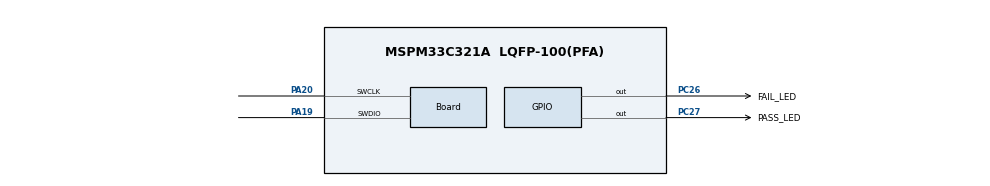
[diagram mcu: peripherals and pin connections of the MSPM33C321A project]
//@cliArgs --device "MSPM33C321A" --package "LQFP-100(PFA)" --part "Default"
//@v2CliArgs --device "MSPM33C321A" --package "LQFP-100(PFA)"
// @cliArgs --board /ti/boards/LP_MSPM33C321A --rtos nortos

/**
 * Import the modules used in this configuration.
 */
const GPIO   = scripting.addModule("/ti/driverlib/GPIO", {}, false);
const GPIO1  = GPIO.addInstance();
const HSADC  = scripting.addModule("/ti/driverlib/HSADC", {}, false);
const HSADC1 = HSADC.addInstance();
const SYSCTL = scripting.addModule("/ti/driverlib/SYSCTL");

/**
 * Write custom configuration values to the imported modules.
 */
GPIO1.$name                               = "GPIO_LEDS";
GPIO1.associatedPins.create(2);
GPIO1.associatedPins[0].$name             = "PASS_LED";
GPIO1.associatedPins[0].launchPadShortcut = "LED2GreenEn";
GPIO1.associatedPins[0].pin.$assign       = "PC27";
GPIO1.associatedPins[1].$name             = "FAIL_LED";
GPIO1.associatedPins[1].launchPadShortcut = "LED2RedEn";
GPIO1.associatedPins[1].pin.$assign       = "PC26";

const Board                       = scripting.addModule("/ti/driverlib/Board", {}, false);
Board.peripheral.$assign          = "DEBUGSS";
Board.peripheral.swclkPin.$assign = "PA20";
Board.peripheral.swdioPin.$assign = "PA19";

HSADC1.$name                 = "HSADC0";
HSADC1.enabledSOCs           = ["ADC_SOC_NUMBER0","ADC_SOC_NUMBER1","ADC_SOC_NUMBER10","ADC_SOC_NUMBER11","ADC_SOC_NUMBER12","ADC_SOC_NUMBER13","ADC_SOC_NUMBER14","ADC_SOC_NUMBER15","ADC_SOC_NUMBER2","ADC_SOC_NUMBER3","ADC_SOC_NUMBER4","ADC_SOC_NUMBER5","ADC_SOC_NUMBER6","ADC_SOC_NUMBER7","ADC_SOC_NUMBER8","ADC_SOC_NUMBER9"];
HSADC1.enabledSEQs           = ["ADC_SEQ_NUMBER1","ADC_SEQ_NUMBER2"];
HSADC1.seqEndSOC             = "ADC_SOC_NUMBER15";
HSADC1.seq1Enable            = true;
HSADC1.seq2Enable            = true;
HSADC1.ppb1AccumulationLimit = "ADC_OVERSAMPLING_LIMIT_8";
HSADC1.enabledInts           = ["ADC_INT_NUMBER_1","ADC_INT_NUMBER_2"];
HSADC1.enableInterrupt1      = true;
HSADC1.enableInterrupt2      = true;
HSADC1.interrupt2SOCSource   = "ADC_SOC_NUMBER15";
HSADC1.seqPreemptMode        = "ADC_PREEMPT_NO_RESTART";
HSADC1.seq2StartSOC          = "ADC_SOC_NUMBER1";
HSADC1.seq2SampleWindow      = 1472;
HSADC1.seq1SampleWindow      = 16;
HSADC1.peripheral.$assign    = "ADC0";

SYSCTL.forceDefaultClkConfig = true;
SYSCTL.peripheral.$assign    = "SYSCTL";

const ProjectConfig              = scripting.addModule("/ti/project_config/ProjectConfig", {}, false);
ProjectConfig.migrationCondition = true;
ProjectConfig.genLinker          = true;
ProjectConfig.genStartup         = true;
ProjectConfig.genOpts            = true;
ProjectConfig.genLibs            = true;
